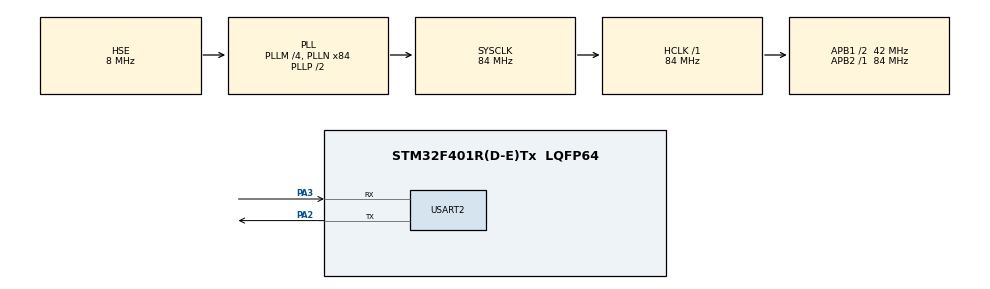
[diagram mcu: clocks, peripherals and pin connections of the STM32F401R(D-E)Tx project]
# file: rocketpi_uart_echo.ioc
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Dma.Request0=USART2_RX
Dma.Request1=USART2_TX
Dma.USART2_RX.0.Direction=DMA_PERIPH_TO_MEMORY
Dma.USART2_RX.0.FIFOMode=DMA_FIFOMODE_DISABLE
Dma.USART2_RX.0.Instance=DMA1_Stream5
Dma.USART2_RX.0.MemDataAlignment=DMA_MDATAALIGN_BYTE
Dma.USART2_RX.0.MemInc=DMA_MINC_ENABLE
Dma.USART2_RX.0.Mode=DMA_NORMAL
Dma.USART2_RX.0.PeriphDataAlignment=DMA_PDATAALIGN_BYTE
Dma.USART2_RX.0.PeriphInc=DMA_PINC_DISABLE
Dma.USART2_RX.0.Priority=DMA_PRIORITY_LOW
Dma.USART2_TX.1.Direction=DMA_MEMORY_TO_PERIPH
Dma.USART2_TX.1.FIFOMode=DMA_FIFOMODE_DISABLE
Dma.USART2_TX.1.Instance=DMA1_Stream6
Dma.USART2_TX.1.MemDataAlignment=DMA_MDATAALIGN_BYTE
Dma.USART2_TX.1.MemInc=DMA_MINC_ENABLE
Dma.USART2_TX.1.Mode=DMA_NORMAL
Dma.USART2_TX.1.PeriphDataAlignment=DMA_PDATAALIGN_BYTE
Dma.USART2_TX.1.PeriphInc=DMA_PINC_DISABLE
Dma.USART2_TX.1.Priority=DMA_PRIORITY_LOW
Mcu.Family=STM32F4
Mcu.Name=STM32F401R(D-E)Tx
Mcu.Package=LQFP64
NVIC.DMA1_Stream5_IRQn=true\:0\:0\:false\:false\:true\:false\:true\:true
NVIC.DMA1_Stream6_IRQn=true\:0\:0\:false\:false\:true\:false\:true\:true
NVIC.PriorityGroup=NVIC_PRIORITYGROUP_4
NVIC.USART2_IRQn=true\:0\:0\:false\:false\:true\:true\:true\:true
PA13.Mode=Serial_Wire
PA13.Signal=SYS_JTMS-SWDIO
PA14.Mode=Serial_Wire
PA14.Signal=SYS_JTCK-SWCLK
PA2.Mode=Asynchronous
PA2.Signal=USART2_TX
PA3.Mode=Asynchronous
PA3.Signal=USART2_RX
PH0\ -\ OSC_IN.Mode=HSE-External-Oscillator
PH0\ -\ OSC_IN.Signal=RCC_OSC_IN
PH1\ -\ OSC_OUT.Mode=HSE-External-Oscillator
PH1\ -\ OSC_OUT.Signal=RCC_OSC_OUT
ProjectManager.HeapSize=0x1000
ProjectManager.StackSize=0x1000
ProjectManager.TargetToolchain=MDK-ARM V5.27
RCC.48MHZClocksFreq_Value=42000000
RCC.AHBFreq_Value=84000000
RCC.APB1CLKDivider=RCC_HCLK_DIV2
RCC.APB1Freq_Value=42000000
RCC.APB1TimFreq_Value=84000000
RCC.APB2Freq_Value=84000000
RCC.APB2TimFreq_Value=84000000
RCC.CortexFreq_Value=84000000
RCC.HCLKFreq_Value=84000000
RCC.HSE_VALUE=8000000
RCC.HSI_VALUE=16000000
RCC.LSE_VALUE=32768
RCC.PLLM=4
RCC.PLLN=84
RCC.PLLSourceVirtual=RCC_PLLSOURCE_HSE
RCC.SYSCLKFreq_VALUE=84000000
RCC.SYSCLKSource=RCC_SYSCLKSOURCE_PLLCLK
RCC.VCOOutputFreq_Value=168000000
USART2.VirtualMode=VM_ASYNC
board=custom

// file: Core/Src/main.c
/* USER CODE BEGIN Header */
/**
  ******************************************************************************
  * @file           : main.c
  * @brief          : Main program body
  ******************************************************************************
  * @attention
  *
  * Copyright (c) 2025 STMicroelectronics.
  * All rights reserved.
  *
  * This software is licensed under terms that can be found in the LICENSE file
  * in the root directory of this software component.
  * If no LICENSE file comes with this software, it is provided AS-IS.
  *
  ******************************************************************************
  */
/* USER CODE END Header */
#include "main.h"
#include "dma.h"
#include "usart.h"
#include "gpio.h"

/* USER CODE BEGIN Includes */
#include <string.h>
/* USER CODE END Includes */

/* USER CODE BEGIN PD */
#define UART_DMA_BUFFER_SIZE 128U  /* 单次回显缓存大小 */
/* USER CODE END PD */

void SystemClock_Config(void);
/* USER CODE BEGIN PFP */
static HAL_StatusTypeDef uart_restart_rx_dma(void);
static void uart_send_string(const char *msg);
static void uart_send_banner(void);
/* USER CODE END PFP */

/* USER CODE BEGIN 0 */
static uint8_t g_uart_rx_buffer[UART_DMA_BUFFER_SIZE];
static uint8_t g_uart_tx_buffer[UART_DMA_BUFFER_SIZE];

/* 重新启动串口空闲中断 DMA 接收，始终准备下一帧数据 */
static HAL_StatusTypeDef uart_restart_rx_dma(void)
{
  HAL_StatusTypeDef status = HAL_UARTEx_ReceiveToIdle_DMA(&huart2,
                                                          g_uart_rx_buffer,
                                                          UART_DMA_BUFFER_SIZE);
  if (status == HAL_OK)
  {
    if (huart2.hdmarx != NULL)
    {
      __HAL_DMA_DISABLE_IT(huart2.hdmarx, DMA_IT_HT);
    }
  }
  return status;
}

/* 阻塞方式发送字符串，主要用于提示和回显 */
static void uart_send_string(const char *msg)
{
  if ((msg == NULL) || (*msg == '\0'))
  {
    return;
  }
  const size_t length = strlen(msg);
  if (length == 0U)
  {
    return;
  }
  if (HAL_UART_Transmit(&huart2,
                        (uint8_t *)msg,
                        (uint16_t)length,
                        HAL_MAX_DELAY) != HAL_OK)
  {
    Error_Handler();
  }
}

/* 打印启动提示，告知用户当前示例用途 */
static void uart_send_banner(void)
{
  uart_send_string("\r\nRocketPi UART echo ready.\r\n");
  uart_send_string("Type any text and it will be echoed back.\r\n> ");
}

/* 串口接收到一帧数据后立即回显，并重新打开 DMA 接收 */
void HAL_UARTEx_RxEventCallback(UART_HandleTypeDef *huart, uint16_t Size)
{
  if ((huart != &huart2) || (Size == 0U))
  {
    return;
  }

  const uint16_t copy_size = (Size <= UART_DMA_BUFFER_SIZE) ? Size : UART_DMA_BUFFER_SIZE;
  memcpy(g_uart_tx_buffer, g_uart_rx_buffer, copy_size);

  if (uart_restart_rx_dma() != HAL_OK)
  {
    Error_Handler();
  }

  if (HAL_UART_Transmit(&huart2, g_uart_tx_buffer, copy_size, HAL_MAX_DELAY) != HAL_OK)
  {
    Error_Handler();
  }
}

/* 若发生串口错误则重新启动 DMA 接收，保证示例持续运行 */
void HAL_UART_ErrorCallback(UART_HandleTypeDef *huart)
{
  if (huart != &huart2)
  {
    return;
  }

  if (uart_restart_rx_dma() != HAL_OK)
  {
    Error_Handler();
  }
}
/* USER CODE END 0 */

int main(void)
{

  /* MCU Configuration--------------------------------------------------------*/

  /* Reset of all peripherals, Initializes the Flash interface and the Systick. */
  HAL_Init();

  /* Configure the system clock */
  SystemClock_Config();

  /* Initialize all configured peripherals */
  MX_GPIO_Init();
  MX_DMA_Init();
  MX_USART2_UART_Init();
  /* USER CODE BEGIN 2 */
  /* 上电后先启动 DMA 接收，再输出提示信息 */
  if (uart_restart_rx_dma() != HAL_OK)
  {
    Error_Handler();
  }
  uart_send_banner();
  /* USER CODE END 2 */

  /* Infinite loop */
  /* USER CODE BEGIN WHILE */
  while (1)
  {
    HAL_Delay(1);
    /* USER CODE END WHILE */

  }
}

void SystemClock_Config(void)
{
  RCC_OscInitTypeDef RCC_OscInitStruct = {0};
  RCC_ClkInitTypeDef RCC_ClkInitStruct = {0};

  /** Configure the main internal regulator output voltage
  */
  __HAL_RCC_PWR_CLK_ENABLE();
  __HAL_PWR_VOLTAGESCALING_CONFIG(PWR_REGULATOR_VOLTAGE_SCALE2);

  /** Initializes the RCC Oscillators according to the specified parameters
  * in the RCC_OscInitTypeDef structure.
  */
  RCC_OscInitStruct.OscillatorType = RCC_OSCILLATORTYPE_HSE;
  RCC_OscInitStruct.HSEState = RCC_HSE_ON;
  RCC_OscInitStruct.PLL.PLLState = RCC_PLL_ON;
  RCC_OscInitStruct.PLL.PLLSource = RCC_PLLSOURCE_HSE;
  RCC_OscInitStruct.PLL.PLLM = 4;
  RCC_OscInitStruct.PLL.PLLN = 84;
  RCC_OscInitStruct.PLL.PLLP = RCC_PLLP_DIV2;
  RCC_OscInitStruct.PLL.PLLQ = 4;
  if (HAL_RCC_OscConfig(&RCC_OscInitStruct) != HAL_OK)
  {
    Error_Handler();
  }

  /** Initializes the CPU, AHB and APB buses clocks
  */
  RCC_ClkInitStruct.ClockType = RCC_CLOCKTYPE_HCLK|RCC_CLOCKTYPE_SYSCLK
                              |RCC_CLOCKTYPE_PCLK1|RCC_CLOCKTYPE_PCLK2;
  RCC_ClkInitStruct.SYSCLKSource = RCC_SYSCLKSOURCE_PLLCLK;
  RCC_ClkInitStruct.AHBCLKDivider = RCC_SYSCLK_DIV1;
  RCC_ClkInitStruct.APB1CLKDivider = RCC_HCLK_DIV2;
  RCC_ClkInitStruct.APB2CLKDivider = RCC_HCLK_DIV1;

  if (HAL_RCC_ClockConfig(&RCC_ClkInitStruct, FLASH_LATENCY_2) != HAL_OK)
  {
    Error_Handler();
  }
}

void Error_Handler(void)
{
  __disable_irq();
  while (1)
  {
  }
}
